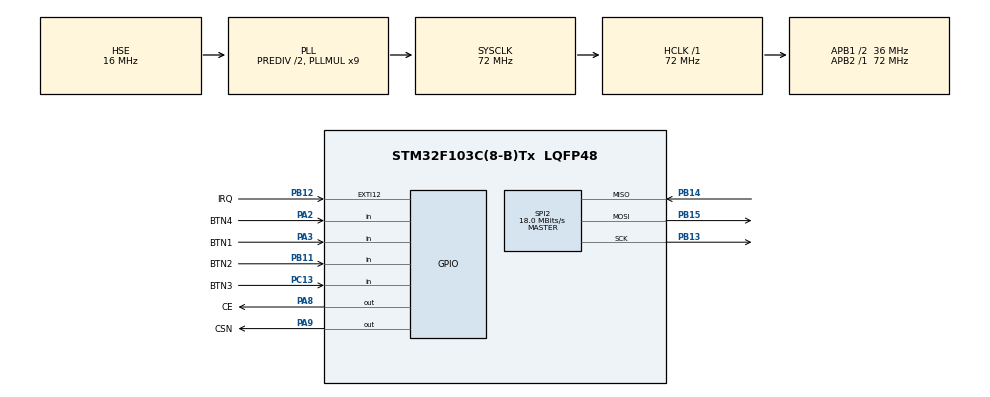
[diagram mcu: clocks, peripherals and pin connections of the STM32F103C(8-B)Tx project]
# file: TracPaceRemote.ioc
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Mcu.Family=STM32F1
Mcu.Name=STM32F103C(8-B)Tx
Mcu.Package=LQFP48
NVIC.EXTI15_10_IRQn=true\:0\:0\:false\:false\:true\:true\:true\:true
NVIC.PriorityGroup=NVIC_PRIORITYGROUP_4
NVIC.TIM2_IRQn=true\:0\:0\:false\:false\:true\:true\:true\:true
PA13.Mode=Trace_Asynchronous_SW
PA13.Signal=SYS_JTMS-SWDIO
PA14.Mode=Trace_Asynchronous_SW
PA14.Signal=SYS_JTCK-SWCLK
PA2.GPIO_Label=BTN4
PA2.Signal=GPIO_Input
PA3.GPIO_Label=BTN1
PA3.Signal=GPIO_Input
PA8.GPIO_Label=CE
PA8.GPIO_Speed=GPIO_SPEED_FREQ_HIGH
PA8.Signal=GPIO_Output
PA9.GPIO_Label=CSN
PA9.GPIO_Speed=GPIO_SPEED_FREQ_HIGH
PA9.Signal=GPIO_Output
PB11.GPIO_Label=BTN2
PB11.Signal=GPIO_Input
PB12.GPIO_Label=IRQ
PB12.Signal=GPXTI12
PB13.Mode=Full_Duplex_Master
PB13.Signal=SPI2_SCK
PB14.Mode=Full_Duplex_Master
PB14.Signal=SPI2_MISO
PB15.Mode=Full_Duplex_Master
PB15.Signal=SPI2_MOSI
PB3.Mode=Trace_Asynchronous_SW
PB3.Signal=SYS_JTDO-TRACESWO
PC13-TAMPER-RTC.GPIO_Label=BTN3
PC13-TAMPER-RTC.Signal=GPIO_Input
PD0-OSC_IN.Mode=HSE-External-Oscillator
PD0-OSC_IN.Signal=RCC_OSC_IN
PD1-OSC_OUT.Mode=HSE-External-Oscillator
PD1-OSC_OUT.Signal=RCC_OSC_OUT
ProjectManager.HeapSize=0x200
ProjectManager.StackSize=0x400
ProjectManager.TargetToolchain=STM32CubeIDE
RCC.AHBFreq_Value=72000000
RCC.APB1CLKDivider=RCC_HCLK_DIV2
RCC.APB1Freq_Value=36000000
RCC.APB1TimFreq_Value=72000000
RCC.APB2Freq_Value=72000000
RCC.APB2TimFreq_Value=72000000
RCC.HCLKFreq_Value=72000000
RCC.HSEDivPLL=RCC_HSE_PREDIV_DIV2
RCC.HSE_VALUE=16000000
RCC.PLLMUL=RCC_PLL_MUL9
RCC.PLLSourceVirtual=RCC_PLLSOURCE_HSE
RCC.SYSCLKFreq_VALUE=72000000
RCC.SYSCLKSource=RCC_SYSCLKSOURCE_PLLCLK
RCC.USBFreq_Value=72000000
SPI2.CalculateBaudRate=18.0 MBits/s
SPI2.Direction=SPI_DIRECTION_2LINES
SPI2.Mode=SPI_MODE_MASTER
SPI2.VirtualType=VM_MASTER
TIM2.Period=1000-1
TIM2.Prescaler=720-1
VP_TIM2_VS_ClockSourceINT.Mode=Internal
board=custom

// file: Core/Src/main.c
/* USER CODE BEGIN Header */
/**
  ******************************************************************************
  * @file           : main.c
  * @brief          : Main program body
  ******************************************************************************
  * @attention
  *
  * Copyright (c) 2023 STMicroelectronics.
  * All rights reserved.
  *
  * This software is licensed under terms that can be found in the LICENSE file
  * in the root directory of this software component.
  * If no LICENSE file comes with this software, it is provided AS-IS.
  *
  ******************************************************************************
  */
/* USER CODE END Header */
#include "main.h"

/* USER CODE BEGIN Includes */
#include "control.h"
#include "input.h"
#include "receiver.h"
/* USER CODE END Includes */

SPI_HandleTypeDef hspi2;

TIM_HandleTypeDef htim2;

void SystemClock_Config(void);
static void MX_GPIO_Init(void);
static void MX_SPI2_Init(void);
static void MX_TIM2_Init(void);

int main(void)
{

  /* MCU Configuration--------------------------------------------------------*/

  /* Reset of all peripherals, Initializes the Flash interface and the Systick. */
  HAL_Init();

  /* Configure the system clock */
  SystemClock_Config();

  /* Initialize all configured peripherals */
  MX_GPIO_Init();
  MX_SPI2_Init();
  MX_TIM2_Init();
  /* USER CODE BEGIN 2 */
  HAL_Delay(100);

  Control_Init();
  /* USER CODE END 2 */

  /* Infinite loop */
  /* USER CODE BEGIN WHILE */
  while (1)
  {
	  Control_Loop();
    /* USER CODE END WHILE */

  }
}

void SystemClock_Config(void)
{
  RCC_OscInitTypeDef RCC_OscInitStruct = {0};
  RCC_ClkInitTypeDef RCC_ClkInitStruct = {0};

  /** Initializes the RCC Oscillators according to the specified parameters
  * in the RCC_OscInitTypeDef structure.
  */
  RCC_OscInitStruct.OscillatorType = RCC_OSCILLATORTYPE_HSE;
  RCC_OscInitStruct.HSEState = RCC_HSE_ON;
  RCC_OscInitStruct.HSEPredivValue = RCC_HSE_PREDIV_DIV2;
  RCC_OscInitStruct.HSIState = RCC_HSI_ON;
  RCC_OscInitStruct.PLL.PLLState = RCC_PLL_ON;
  RCC_OscInitStruct.PLL.PLLSource = RCC_PLLSOURCE_HSE;
  RCC_OscInitStruct.PLL.PLLMUL = RCC_PLL_MUL9;
  if (HAL_RCC_OscConfig(&RCC_OscInitStruct) != HAL_OK)
  {
    Error_Handler();
  }

  /** Initializes the CPU, AHB and APB buses clocks
  */
  RCC_ClkInitStruct.ClockType = RCC_CLOCKTYPE_HCLK|RCC_CLOCKTYPE_SYSCLK
                              |RCC_CLOCKTYPE_PCLK1|RCC_CLOCKTYPE_PCLK2;
  RCC_ClkInitStruct.SYSCLKSource = RCC_SYSCLKSOURCE_PLLCLK;
  RCC_ClkInitStruct.AHBCLKDivider = RCC_SYSCLK_DIV1;
  RCC_ClkInitStruct.APB1CLKDivider = RCC_HCLK_DIV2;
  RCC_ClkInitStruct.APB2CLKDivider = RCC_HCLK_DIV1;

  if (HAL_RCC_ClockConfig(&RCC_ClkInitStruct, FLASH_LATENCY_2) != HAL_OK)
  {
    Error_Handler();
  }
}

static void MX_SPI2_Init(void)
{

  /* SPI2 parameter configuration*/
  hspi2.Instance = SPI2;
  hspi2.Init.Mode = SPI_MODE_MASTER;
  hspi2.Init.Direction = SPI_DIRECTION_2LINES;
  hspi2.Init.DataSize = SPI_DATASIZE_8BIT;
  hspi2.Init.CLKPolarity = SPI_POLARITY_LOW;
  hspi2.Init.CLKPhase = SPI_PHASE_1EDGE;
  hspi2.Init.NSS = SPI_NSS_SOFT;
  hspi2.Init.BaudRatePrescaler = SPI_BAUDRATEPRESCALER_2;
  hspi2.Init.FirstBit = SPI_FIRSTBIT_MSB;
  hspi2.Init.TIMode = SPI_TIMODE_DISABLE;
  hspi2.Init.CRCCalculation = SPI_CRCCALCULATION_DISABLE;
  hspi2.Init.CRCPolynomial = 10;
  if (HAL_SPI_Init(&hspi2) != HAL_OK)
  {
    Error_Handler();
  }

}

static void MX_TIM2_Init(void)
{

  TIM_ClockConfigTypeDef sClockSourceConfig = {0};
  TIM_MasterConfigTypeDef sMasterConfig = {0};

  htim2.Instance = TIM2;
  htim2.Init.Prescaler = 720-1;
  htim2.Init.CounterMode = TIM_COUNTERMODE_UP;
  htim2.Init.Period = 1000-1;
  htim2.Init.ClockDivision = TIM_CLOCKDIVISION_DIV1;
  htim2.Init.AutoReloadPreload = TIM_AUTORELOAD_PRELOAD_DISABLE;
  if (HAL_TIM_Base_Init(&htim2) != HAL_OK)
  {
    Error_Handler();
  }
  sClockSourceConfig.ClockSource = TIM_CLOCKSOURCE_INTERNAL;
  if (HAL_TIM_ConfigClockSource(&htim2, &sClockSourceConfig) != HAL_OK)
  {
    Error_Handler();
  }
  sMasterConfig.MasterOutputTrigger = TIM_TRGO_RESET;
  sMasterConfig.MasterSlaveMode = TIM_MASTERSLAVEMODE_DISABLE;
  if (HAL_TIMEx_MasterConfigSynchronization(&htim2, &sMasterConfig) != HAL_OK)
  {
    Error_Handler();
  }
  /* USER CODE BEGIN TIM2_Init 2 */
  if (HAL_TIM_Base_Start_IT(&htim2) != HAL_OK) {
  		Error_Handler();
  	}
  /* USER CODE END TIM2_Init 2 */

}

static void MX_GPIO_Init(void)
{
  GPIO_InitTypeDef GPIO_InitStruct = {0};

  /* GPIO Ports Clock Enable */
  __HAL_RCC_GPIOC_CLK_ENABLE();
  __HAL_RCC_GPIOD_CLK_ENABLE();
  __HAL_RCC_GPIOA_CLK_ENABLE();
  __HAL_RCC_GPIOB_CLK_ENABLE();

  /*Configure GPIO pin Output Level */
  HAL_GPIO_WritePin(GPIOA, CE_Pin|CSN_Pin, GPIO_PIN_RESET);

  /*Configure GPIO pin : BTN3_Pin */
  GPIO_InitStruct.Pin = BTN3_Pin;
  GPIO_InitStruct.Mode = GPIO_MODE_INPUT;
  GPIO_InitStruct.Pull = GPIO_NOPULL;
  HAL_GPIO_Init(BTN3_GPIO_Port, &GPIO_InitStruct);

  /*Configure GPIO pins : BTN4_Pin BTN1_Pin */
  GPIO_InitStruct.Pin = BTN4_Pin|BTN1_Pin;
  GPIO_InitStruct.Mode = GPIO_MODE_INPUT;
  GPIO_InitStruct.Pull = GPIO_NOPULL;
  HAL_GPIO_Init(GPIOA, &GPIO_InitStruct);

  /*Configure GPIO pin : BTN2_Pin */
  GPIO_InitStruct.Pin = BTN2_Pin;
  GPIO_InitStruct.Mode = GPIO_MODE_INPUT;
  GPIO_InitStruct.Pull = GPIO_NOPULL;
  HAL_GPIO_Init(BTN2_GPIO_Port, &GPIO_InitStruct);

  /*Configure GPIO pin : IRQ_Pin */
  GPIO_InitStruct.Pin = IRQ_Pin;
  GPIO_InitStruct.Mode = GPIO_MODE_IT_RISING;
  GPIO_InitStruct.Pull = GPIO_NOPULL;
  HAL_GPIO_Init(IRQ_GPIO_Port, &GPIO_InitStruct);

  /*Configure GPIO pins : CE_Pin CSN_Pin */
  GPIO_InitStruct.Pin = CE_Pin|CSN_Pin;
  GPIO_InitStruct.Mode = GPIO_MODE_OUTPUT_PP;
  GPIO_InitStruct.Pull = GPIO_NOPULL;
  GPIO_InitStruct.Speed = GPIO_SPEED_FREQ_HIGH;
  HAL_GPIO_Init(GPIOA, &GPIO_InitStruct);

  /* EXTI interrupt init*/
  HAL_NVIC_SetPriority(EXTI15_10_IRQn, 0, 0);
  HAL_NVIC_EnableIRQ(EXTI15_10_IRQn);

}

/* USER CODE BEGIN 4 */
void HAL_TIM_PeriodElapsedCallback(TIM_HandleTypeDef *htim) {
	Input_TimerHandler();
}

void HAL_GPIO_EXTI_Callback(uint16_t GPIO_Pin) {
	Receiver_Handler();
}
/* USER CODE END 4 */

void Error_Handler(void)
{
  __disable_irq();
  while (1)
  {
  }
}
